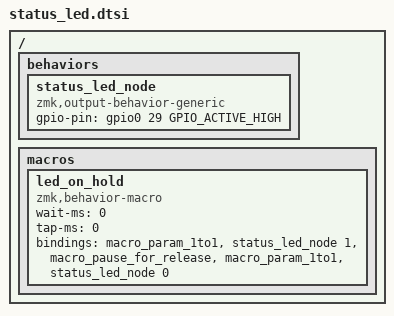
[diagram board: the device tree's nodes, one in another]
/ {
    behaviors {
        status_led_node: status_led_node {
            compatible = "zmk,output-behavior-generic";
            #binding-cells = <0>;
            gpio-pin = <&gpio0 29 GPIO_ACTIVE_HIGH>;
        };
    };

    macros {
        led_on_hold: led_on_hold {
            compatible = "zmk,behavior-macro";
            #binding-cells = <0>;
            wait-ms = <0>;
            tap-ms = <0>;
            bindings
                = <&macro_param_1to1 &status_led_node 1> 
                , <&macro_pause_for_release>        
                , <&macro_param_1to1 &status_led_node 0>; 
        };
    };
};
